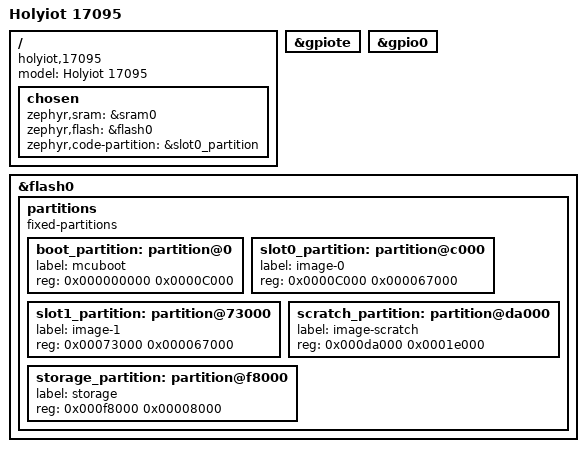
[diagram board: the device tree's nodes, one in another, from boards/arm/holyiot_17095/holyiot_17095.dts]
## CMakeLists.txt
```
# Boilerplate code, which pulls in the Zephyr build system.
cmake_minimum_required(VERSION 3.13.1)
include($ENV{ZEPHYR_BASE}/cmake/app/boilerplate.cmake NO_POLICY_SCOPE)
project(mesh-onoff)

# Add your source file to the "app" target. This must come after
# the boilerplate code, which defines the target.
target_sources(app PRIVATE src/main.c)
```

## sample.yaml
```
sample:
  name: Bluetooth Mesh
tests:
  sample.bluetooth.mesh.onoff:
    platform_whitelist: nrf52_blenano2
    tags: bluetooth
    harness: bluetooth
```

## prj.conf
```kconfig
CONFIG_MAIN_STACK_SIZE=512
CONFIG_SYSTEM_WORKQUEUE_STACK_SIZE=2048
CONFIG_GPIO=y
CONFIG_BT_SETTINGS=y
CONFIG_FLASH=y
CONFIG_FLASH_PAGE_LAYOUT=y
CONFIG_FLASH_MAP=y
CONFIG_NVS=y
CONFIG_SETTINGS=y
CONFIG_BT_MESH_RPL_STORE_TIMEOUT=600
CONFIG_BOOT_BANNER=y
CONFIG_BT_OBSERVER=y
CONFIG_BT_BROADCASTER=y
CONFIG_BT_CTLR_DUP_FILTER_LEN=0
CONFIG_BT_CTLR_LE_ENC=n
CONFIG_BT_CTLR_LE_PING=n
CONFIG_BT_DATA_LEN_UPDATE=n
CONFIG_BT_PHY_UPDATE=n
CONFIG_BT_CTLR_CHAN_SEL_2=n
CONFIG_BT_CTLR_MIN_USED_CHAN=n
CONFIG_BT_CTLR_ADV_EXT=n
CONFIG_BT_CTLR_PRIVACY=n
CONFIG_BT_PERIPHERAL=y
CONFIG_BT=y
CONFIG_BT_TINYCRYPT_ECC=y
CONFIG_BT_L2CAP_TX_BUF_COUNT=8
CONFIG_BT_MESH=y
CONFIG_BT_MESH_RELAY=y
CONFIG_BT_MESH_LOW_POWER=n
CONFIG_BT_MESH_FRIEND=n
CONFIG_BT_MESH_ADV_BUF_COUNT=20
CONFIG_BT_MESH_TX_SEG_MAX=6
CONFIG_BT_MESH_PB_GATT=y
CONFIG_BT_MESH_PB_ADV=y
CONFIG_BT_MESH_GATT_PROXY=y
CONFIG_BT_MESH_CFG_CLI=y
CONFIG_BT_MESH_SUBNET_COUNT=2
CONFIG_BT_MESH_APP_KEY_COUNT=2
CONFIG_BT_MESH_MODEL_KEY_COUNT=2
CONFIG_BT_MESH_MODEL_GROUP_COUNT=2
CONFIG_BT_MESH_LABEL_COUNT=3
CONFIG_UART_CONSOLE=y
CONFIG_BT_DEBUG_LOG=y
CONFIG_BT_MESH_DEBUG=y
CONFIG_BT_RX_STACK_SIZE=4096
CONFIG_BT_MAX_CONN=1
CONFIG_BT_CTLR_RX_BUFFERS=6
CONFIG_BT_CTLR_TX_BUFFERS=4
CONFIG_BT_HCI_CMD_COUNT=4
CONFIG_BT_ATT_PREPARE_COUNT=2
CONFIG_BT_CTLR_TX_PWR_PLUS_4=y
```

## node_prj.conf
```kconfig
CONFIG_INIT_STACKS=y
CONFIG_MAIN_STACK_SIZE=512
CONFIG_DISPLAY=y
CONFIG_SYSTEM_WORKQUEUE_STACK_SIZE=2048
CONFIG_GPIO=y

CONFIG_BT_SETTINGS=y
CONFIG_FLASH=y
CONFIG_FLASH_PAGE_LAYOUT=y
CONFIG_FLASH_MAP=y
CONFIG_NVS=y
CONFIG_SETTINGS=y

CONFIG_BT=y
CONFIG_BT_TINYCRYPT_ECC=y
CONFIG_BT_RX_STACK_SIZE=1100
CONFIG_BT_RX_BUF_COUNT=3
CONFIG_BT_DISCARDABLE_BUF_COUNT=3

CONFIG_BT_CTLR_DUP_FILTER_LEN=0
CONFIG_BT_OBSERVER=y
CONFIG_BT_BROADCASTER=y

CONFIG_BT_CTLR_LE_ENC=n
CONFIG_BT_CTLR_LE_PING=n
CONFIG_BT_DATA_LEN_UPDATE=n
CONFIG_BT_PHY_UPDATE=n
CONFIG_BT_CTLR_CHAN_SEL_2=n
CONFIG_BT_CTLR_MIN_USED_CHAN=n
CONFIG_BT_CTLR_ADV_EXT=n
CONFIG_BT_CTLR_PRIVACY=n

CONFIG_BT_MESH=y
CONFIG_BT_MESH_RX_SDU_MAX=36
CONFIG_BT_MESH_RELAY=y

#CONFIG_BT_MESH_LOW_POWER=y

#CONFIG_BT_MESH_SELF_TEST=y
#CONFIG_BT_MESH_IV_UPDATE_TEST=y

CONFIG_BT_MESH_SUBNET_COUNT=1
CONFIG_BT_MESH_APP_KEY_COUNT=1
CONFIG_BT_MESH_MODEL_GROUP_COUNT=1
CONFIG_BT_MESH_LABEL_COUNT=0

#CONFIG_BT_DEBUG_LOG=y

#CONFIG_BT_MESH_DEBUG=y
#CONFIG_BT_MESH_DEBUG_NET=y
#CONFIG_BT_MESH_DEBUG_TRANS=y
#CONFIG_BT_MESH_DEBUG_PROV=y
#CONFIG_BT_MESH_DEBUG_BEACON=y
#CONFIG_BT_MESH_DEBUG_CRYPTO=y
#CONFIG_BT_MESH_DEBUG_ADV=y
#CONFIG_BT_MESH_DEBUG_ACCESS=y
```

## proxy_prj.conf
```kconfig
#CONFIG_INIT_STACKS=y
CONFIG_SYSTEM_WORKQUEUE_STACK_SIZE=2048

CONFIG_BT_SETTINGS=y
CONFIG_FLASH=y
CONFIG_FLASH_PAGE_LAYOUT=y
CONFIG_FLASH_MAP=y
CONFIG_NVS=y
CONFIG_SETTINGS=y

CONFIG_BT_OBSERVER=y
CONFIG_BT_BROADCASTER=y
CONFIG_BT_CTLR_DUP_FILTER_LEN=0
CONFIG_BT_CTLR_LE_ENC=n
CONFIG_BT_CTLR_LE_PING=n
CONFIG_BT_DATA_LEN_UPDATE=n
CONFIG_BT_PHY_UPDATE=n
CONFIG_BT_CTLR_CHAN_SEL_2=n
CONFIG_BT_CTLR_MIN_USED_CHAN=n
CONFIG_BT_CTLR_ADV_EXT=n
CONFIG_BT_CTLR_PRIVACY=n

CONFIG_BT_PERIPHERAL=y

CONFIG_BT=y
CONFIG_BT_TINYCRYPT_ECC=y
CONFIG_BT_L2CAP_RX_MTU=69
CONFIG_BT_L2CAP_TX_MTU=69
CONFIG_BT_L2CAP_TX_BUF_COUNT=5

CONFIG_BT_MESH=y
CONFIG_BT_MESH_RELAY=y
CONFIG_BT_MESH_LOW_POWER=n
CONFIG_BT_MESH_FRIEND=y
CONFIG_BT_MESH_FRIEND_QUEUE_SIZE=16

CONFIG_BT_MESH_PB_GATT=y
CONFIG_BT_MESH_PB_ADV=y
CONFIG_BT_MESH_GATT_PROXY=y

#CONFIG_BT_MESH_LPN_SCAN_LATENCY=30
#CONFIG_BT_MESH_LPN_RECV_DELAY=40
#CONFIG_BT_MESH_LPN_POLL_TIMEOUT=300

CONFIG_BT_MESH_SUBNET_COUNT=2
CONFIG_BT_MESH_APP_KEY_COUNT=2
CONFIG_BT_MESH_MODEL_GROUP_COUNT=2
CONFIG_BT_MESH_LABEL_COUNT=3

#CONFIG_BT_MESH_IV_UPDATE_TEST=y

#CONFIG_UART_CONSOLE=n
#CONFIG_BT_DEBUG_MONITOR=y
CONFIG_BT_DEBUG_LOG=y

CONFIG_BT_MESH_DEBUG=y
#CONFIG_BT_MESH_DEBUG_PROV=y
#CONFIG_BT_MESH_DEBUG_PROXY=y
#CONFIG_BT_MESH_DEBUG_BEACON=y
CONFIG_BT_MESH_DEBUG_NET=y
CONFIG_BT_MESH_DEBUG_TRANS=y
CONFIG_BT_MESH_DEBUG_SETTINGS=y
#CONFIG_BT_MESH_DEBUG_LOW_POWER=y
CONFIG_BT_MESH_DEBUG_FRIEND=y
#CONFIG_BT_MESH_DEBUG_MODEL=y
#CONFIG_BT_MESH_DEBUG_ACCESS=y
#CONFIG_BT_MESH_DEBUG_CRYPTO=y
#CONFIG_BT_MESH_DEBUG_ADV=y
#CONFIG_BT_MESH_SELF_TEST=y
CONFIG_BT_CTLR_TX_PWR_PLUS_4=y
```

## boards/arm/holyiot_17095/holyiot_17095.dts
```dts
/*
 * Copyright (c) 2019 Henrik Brix Andersen <henrik@brixandersen.dk>
 *
 * SPDX-License-Identifier: Apache-2.0
 */

/dts-v1/;
#include <nordic/nrf52832_qfaa.dtsi>

/ {
	model = "Holyiot 17095";
	compatible = "holyiot,17095", "nordic,nrf52832-qfaa",
		     "nordic,nrf52832";

	chosen {
		zephyr,sram = &sram0;
		zephyr,flash = &flash0;
		zephyr,code-partition = &slot0_partition;
	};
};

&gpiote {
	status = "okay";
};

&gpio0 {
	status = "okay";
};

&flash0 {
	/*
	 * For more information, see:
	 * http://docs.zephyrproject.org/latest/guides/dts/index.html#flash-partitions
	 */
	partitions {
		compatible = "fixed-partitions";
		#address-cells = <1>;
		#size-cells = <1>;

		boot_partition: partition@0 {
			label = "mcuboot";
			reg = <0x000000000 0x0000C000>;
		};
		slot0_partition: partition@c000 {
			label = "image-0";
			reg = <0x0000C000 0x000067000>;
		};
		slot1_partition: partition@73000 {
			label = "image-1";
			reg = <0x00073000 0x000067000>;
		};
		scratch_partition: partition@da000 {
			label = "image-scratch";
			reg = <0x000da000 0x0001e000>;
		};

		/*
		 * The flash starting at 0x000f8000 and ending at
		 * 0x000fffff is reserved for use by the application.
		 */

		/* Storage partition will be used by FCB/NFFS/NVS if enabled. */
		storage_partition: partition@f8000 {
			label = "storage";
			reg = <0x000f8000 0x00008000>;
		};
	};
};
```

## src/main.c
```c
#include <bluetooth/bluetooth.h>
#include "mesh_logic.h"
#include "ts_buttons_logic.h"
#include "relays_logic.h"
#include "leds_logic.h"

void main(void) {
  init_leds();
  init_relays();
  init_ts();

  /* Initialize the Bluetooth Subsystem */
  int err;
  err = bt_enable(bt_ready);
  if (err) {

  }
}
```

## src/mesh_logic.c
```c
#include <stdint.h>
#include <bluetooth/bluetooth.h>
#include <bluetooth/conn.h>
#include <bluetooth/hci.h>
#include <bluetooth/l2cap.h>
#include <bluetooth/mesh.h>
#include <settings/settings.h>
#include "mesh_logic.h"
#include "relays_logic.h"
#include "node_conf.h"


/* Model Operation Codes */
#define BT_MESH_MODEL_OP_GEN_ONOFF_GET        BT_MESH_MODEL_OP_2(0x82, 0x01)
#define BT_MESH_MODEL_OP_GEN_ONOFF_SET        BT_MESH_MODEL_OP_2(0x82, 0x02)
#define BT_MESH_MODEL_OP_GEN_ONOFF_SET_UNACK  BT_MESH_MODEL_OP_2(0x82, 0x03)
#define BT_MESH_MODEL_OP_GEN_ONOFF_STATUS     BT_MESH_MODEL_OP_2(0x82, 0x04)

static void gen_onoff_set(struct bt_mesh_model *model, struct bt_mesh_msg_ctx *ctx, struct net_buf_simple *buf);
static void gen_onoff_set_unack(struct bt_mesh_model *model, struct bt_mesh_msg_ctx *ctx, struct net_buf_simple *buf);
static void gen_onoff_get(struct bt_mesh_model *model, struct bt_mesh_msg_ctx *ctx, struct net_buf_simple *buf);
static void gen_onoff_status(struct bt_mesh_model *model, struct bt_mesh_msg_ctx *ctx, struct net_buf_simple *buf);

/*
 * Server Configuration Declaration
 */

static struct bt_mesh_cfg_srv cfg_srv = {
  .relay = BT_MESH_RELAY_DISABLED,
  .beacon = BT_MESH_BEACON_ENABLED,
#if defined(CONFIG_BT_MESH_FRIEND)
  .frnd = BT_MESH_FRIEND_ENABLED,
#else
  .frnd = BT_MESH_FRIEND_NOT_SUPPORTED,
#endif
#if defined(CONFIG_BT_MESH_GATT_PROXY)
  .gatt_proxy = BT_MESH_GATT_PROXY_ENABLED,
#else
  .gatt_proxy = BT_MESH_GATT_PROXY_NOT_SUPPORTED,
#endif
  .default_ttl = 7,

  /* 3 transmissions with 20ms interval */
  .net_transmit = BT_MESH_TRANSMIT(2, 20),
  .relay_retransmit = BT_MESH_TRANSMIT(2, 20)
};

/*
 * Client Configuration Declaration
 */

static struct bt_mesh_cfg_cli cfg_cli = {};

/*
 * Health Server Declaration
 */

static struct bt_mesh_health_srv health_srv = {};

/*
 * Publication Declarations
 *
 * The publication messages are initialized to the
 * the size of the opcode + content
 *
 * For publication, the message must be in static or global as
 * it is re-transmitted several times. This occurs
 * after the function that called bt_mesh_model_publish() has
 * exited and the stack is no longer valid.
 *
 * Note that the additional 4 bytes for the AppMIC is not needed
 * because it is added to a stack variable at the time a
 * transmission occurs.
 *
 */

BT_MESH_HEALTH_PUB_DEFINE(health_pub, 0);

BT_MESH_MODEL_PUB_DEFINE(gen_onoff_pub_srv_ch1, NULL, 2 + 1);
BT_MESH_MODEL_PUB_DEFINE(gen_onoff_pub_cli_ch1, NULL, 2 + 1);

#if LIGHT_CHANNELS == 2
BT_MESH_MODEL_PUB_DEFINE(gen_onoff_pub_srv_ch2, NULL, 2 + 1);
BT_MESH_MODEL_PUB_DEFINE(gen_onoff_pub_cli_ch2, NULL, 2 + 1);
#endif

/*
 * Models in an element must have unique op codes.
 *
 * The mesh stack dispatches a message to the first model in an element
 * that is also bound to an app key and supports the op code in the
 * received message.
 *
 */

/*
 * OnOff Model Server Op Dispatch Table
 *
 */

static const struct bt_mesh_model_op gen_onoff_srv_op[] = {
  { BT_MESH_MODEL_OP_GEN_ONOFF_GET, 0, gen_onoff_get },
  { BT_MESH_MODEL_OP_GEN_ONOFF_SET, 1, gen_onoff_set },
  { BT_MESH_MODEL_OP_GEN_ONOFF_SET_UNACK, 1, gen_onoff_set_unack },
  BT_MESH_MODEL_OP_END
};

/*
 * OnOff Model Client Op Dispatch Table
 */

static const struct bt_mesh_model_op gen_onoff_cli_op[] = {
  { BT_MESH_MODEL_OP_GEN_ONOFF_STATUS, 1, gen_onoff_status },
  BT_MESH_MODEL_OP_END
};

/*
 *
 * Element Model Declarations
 *
 * Element 0 Root Models
 */

static uint8_t light_channel_idx[] = {
  0,
#if LIGHT_CHANNELS == 2
  1,
#endif
};

static struct bt_mesh_model root_models[] = {
  BT_MESH_MODEL_CFG_SRV(&cfg_srv),
  BT_MESH_MODEL_CFG_CLI(&cfg_cli),
  BT_MESH_MODEL_HEALTH_SRV(&health_srv, &health_pub)
};

static struct bt_mesh_model secondary_models_ch1[] = {
  BT_MESH_MODEL(BT_MESH_MODEL_ID_GEN_ONOFF_SRV, gen_onoff_srv_op, &gen_onoff_pub_srv_ch1, &light_channel_idx[0]),
  BT_MESH_MODEL(BT_MESH_MODEL_ID_GEN_ONOFF_CLI, gen_onoff_cli_op, &gen_onoff_pub_cli_ch1, &light_channel_idx[0])
};

#if LIGHT_CHANNELS == 2
static struct bt_mesh_model secondary_models_ch2[] = {
  BT_MESH_MODEL(BT_MESH_MODEL_ID_GEN_ONOFF_SRV, gen_onoff_srv_op, &gen_onoff_pub_srv_ch2, &light_channel_idx[1]),
  BT_MESH_MODEL(BT_MESH_MODEL_ID_GEN_ONOFF_CLI, gen_onoff_cli_op, &gen_onoff_pub_cli_ch2, &light_channel_idx[1])
};
#endif


/*
 * Button to Client Model Assignments
 */

static struct bt_mesh_model *mod_cli_ts_btn[] = {
  &secondary_models_ch1[1],
#if LIGHT_CHANNELS == 2
  &secondary_models_ch2[1],
#endif
};

/*
 * Root Element Declarations
 */

static struct bt_mesh_elem elements[] = {
  BT_MESH_ELEM(0, root_models, BT_MESH_MODEL_NONE),
  BT_MESH_ELEM(0, secondary_models_ch1, BT_MESH_MODEL_NONE),
#if LIGHT_CHANNELS == 2
  BT_MESH_ELEM(0, secondary_models_ch2, BT_MESH_MODEL_NONE),
#endif
};

static const struct bt_mesh_comp comp = {
  .cid = BT_COMP_ID_LF,
  .elem = elements,
  .elem_count = ARRAY_SIZE(elements)
};

static uint16_t primary_addr;
static uint16_t primary_net_idx;

/*
 * Generic OnOff Model Server Message Handlers
 *
 * Mesh Model Specification 3.1.1
 *
 */

static void gen_onoff_get(struct bt_mesh_model *model, struct bt_mesh_msg_ctx *ctx, struct net_buf_simple *buf) {
  NET_BUF_SIMPLE_DEFINE(msg, 2 + 1 + 4);

  uint8_t *channel = (uint8_t*)model->user_data;

  bt_mesh_model_msg_init(&msg, BT_MESH_MODEL_OP_GEN_ONOFF_STATUS);
  net_buf_simple_add_u8(&msg, get_relay_state(*channel));

  if (bt_mesh_model_send(model, ctx, &msg, NULL, NULL)) {

  }
}

static void gen_onoff_set_unack(struct bt_mesh_model *model, struct bt_mesh_msg_ctx *ctx, struct net_buf_simple *buf) {
  struct net_buf_simple *msg = model->pub->msg;
  uint8_t *channel = (uint8_t *)model->user_data;

  set_relay_state(*channel, net_buf_simple_pull_u8(buf));

  if (model->pub->addr != BT_MESH_ADDR_UNASSIGNED) {
    bt_mesh_model_msg_init(msg, BT_MESH_MODEL_OP_GEN_ONOFF_STATUS);
    net_buf_simple_add_u8(msg, get_relay_state(*channel));
    int err = bt_mesh_model_publish(model);
    if (err) {

    }
  }
}

static void gen_onoff_set(struct bt_mesh_model *model, struct bt_mesh_msg_ctx *ctx, struct net_buf_simple *buf) {
  printk("gen_onoff_set\n");

  gen_onoff_set_unack(model, ctx, buf);
  gen_onoff_get(model, ctx, buf);
}

static void gen_onoff_status(struct bt_mesh_model *model, struct bt_mesh_msg_ctx *ctx, struct net_buf_simple *buf) {

}

static void prov_complete(u16_t net_idx, u16_t addr) {
  primary_addr = addr;
  primary_net_idx = net_idx;
}

static void prov_reset(void) {
  bt_mesh_prov_enable(BT_MESH_PROV_ADV | BT_MESH_PROV_GATT);
}

static uint8_t dev_uuid[16] = {0xdd, 0xdd};

/* Disable OOB security */

static const struct bt_mesh_prov prov = {
  .uuid = dev_uuid,
  .output_size = 0,
  .output_actions = 0,
  .output_number = 0,
  .complete = prov_complete,
  .reset = prov_reset
};

/*
 * Bluetooth Ready Callback
 */

void bt_ready(int err) {
  struct bt_le_oob oob;

  if (err) {
    return;
  }

  err = bt_mesh_init(&prov, &comp);
  if (err) {;
    return;
  }

  if (IS_ENABLED(CONFIG_SETTINGS)) {
    settings_load();
  }

  /* Use identity address as device UUID */
  if (bt_le_oob_get_local(BT_ID_DEFAULT, &oob)) {

  } else {
    memcpy(dev_uuid, oob.addr.a.val, 6);
  }

  bt_mesh_prov_enable(BT_MESH_PROV_GATT | BT_MESH_PROV_ADV);
}

void mesh_publish_state(uint8_t channel, uint8_t new_state) {
  struct bt_mesh_model *mod_cli = mod_cli_ts_btn[channel];
  struct bt_mesh_model_pub *pub_cli = mod_cli->pub;

  if (pub_cli->addr == BT_MESH_ADDR_UNASSIGNED) {
    return;
  }

  bt_mesh_model_msg_init(pub_cli->msg, BT_MESH_MODEL_OP_GEN_ONOFF_SET);
  net_buf_simple_add_u8(pub_cli->msg, new_state);

  int err = bt_mesh_model_publish(mod_cli);
  if (err) {

  }
}
```

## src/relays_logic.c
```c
#include <stdint.h>
#include <device.h>
#include <drivers/gpio.h>
#include "relays_logic.h"
#include "leds_logic.h"
#include "mesh_logic.h"
#include "node_conf.h"


#define OFF 0
#define ON  1

#define LOW  0
#define HIGH 1

#define RELAY_INIT_TIMEOUT_MS 1500
#define RELAY_TRIGGER_PULSE_DURATION_MS 20

static struct device *gpio_dev_port;
static uint8_t coil_pin;
static uint8_t ch_state[LIGHT_CHANNELS];

static uint8_t RELAY_COIL[][2] = {
  { RELAY1_RESET_PIN, RELAY1_SET_PIN },
#if LIGHT_CHANNELS == 2
  { RELAY2_RESET_PIN, RELAY2_SET_PIN }
#endif
};

static void relay_pulse_timeout(struct k_timer *tim);
K_TIMER_DEFINE(relay_pulse_timer, relay_pulse_timeout, NULL);

static void relay_init_timeout(struct k_timer *tim);
K_TIMER_DEFINE(relay_startup_timer, relay_init_timeout, NULL);


static void relay_pulse_timeout(struct k_timer *tim) {
  gpio_pin_write(gpio_dev_port, coil_pin, LOW);
}

uint8_t get_relay_state(uint8_t channel) {
  return ch_state[channel];
}

void set_relay_state(uint8_t channel, uint8_t new_state) {
  ch_state[channel] = new_state;
  coil_pin = RELAY_COIL[channel][new_state];

  gpio_pin_write(gpio_dev_port, coil_pin, HIGH);
  k_timer_start(&relay_pulse_timer, K_MSEC(RELAY_TRIGGER_PULSE_DURATION_MS), 0);
  set_led_state(new_state);
  mesh_publish_state(channel, ch_state[channel]);
}

void relay_toggle(uint8_t channel) {
  ch_state[channel] = !ch_state[channel];

  set_relay_state(channel, ch_state[channel]);
}

static void relay_init_timeout(struct k_timer *tim) {
#ifdef VSENSE_PIN
  uint32_t switch_state = 0;
  gpio_pin_read(gpio_dev_port, VSENSE_PIN, &switch_state);
#endif

#ifdef VSENSE_PIN
  if (switch_state == ON) {
#endif
    set_relay_state(LIGHT_CHANNEL_1_INDEX, OFF);
#if LIGHT_CHANNELS == 2
    set_relay_state(LIGHT_CHANNEL_2_INDEX, OFF);
#endif
#ifdef VSENSE_PIN
  }
#endif
}

void init_relays(void) {
  gpio_dev_port = device_get_binding("GPIO_0");

  // Channel 1 relay coils
  gpio_pin_configure(gpio_dev_port, RELAY1_SET_PIN, GPIO_DIR_OUT);
  gpio_pin_configure(gpio_dev_port, RELAY1_RESET_PIN, GPIO_DIR_OUT);
  gpio_pin_write(gpio_dev_port, RELAY1_SET_PIN, LOW);
  gpio_pin_write(gpio_dev_port, RELAY1_RESET_PIN, LOW);

#if LIGHT_CHANNELS == 2
  // Channel 2 relay coils
  gpio_pin_configure(gpio_dev_port, RELAY2_SET_PIN, GPIO_DIR_OUT);
  gpio_pin_configure(gpio_dev_port, RELAY2_RESET_PIN, GPIO_DIR_OUT);
  gpio_pin_write(gpio_dev_port, RELAY2_SET_PIN, LOW);
  gpio_pin_write(gpio_dev_port, RELAY2_RESET_PIN, LOW);
#endif

#ifdef VSENSE_PIN
  gpio_pin_configure(gpio_dev_port, VSENSE_PIN, (GPIO_DIR_IN | GPIO_PUD_NORMAL));
#endif

  // reset relays to the OFF state after some time when system starts
  k_timer_start(&relay_startup_timer, K_MSEC(RELAY_INIT_TIMEOUT_MS), 0);
}
```

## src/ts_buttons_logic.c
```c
#include <stdint.h>
#include <device.h>
#include <drivers/gpio.h>
#include <drivers/pwm.h>
#include "ts_buttons_logic.h"
#include "relays_logic.h"
#include "node_conf.h"

#define LOW  0
#define HIGH 1

#define PWM_DUTY_CYCLE_PERCENT 30
#define PWM_FREQUENCY_HZ 100000
#define PWM_PERIOD_USEC (1000000 / PWM_FREQUENCY_HZ)
#define PWM_PULSE_US (PWM_PERIOD_USEC * PWM_DUTY_CYCLE_PERCENT) / 100

#define BUTTON_DEBOUNCE_INTERVAL_MS 250

static struct gpio_callback ts_cb;

static void button_pressed(struct device *dev, struct gpio_callback *cb, u32_t pin_pos) {
  static uint32_t last_press_timestamp;

  // simple debouncing
  if ((k_uptime_get_32() - last_press_timestamp) >= BUTTON_DEBOUNCE_INTERVAL_MS) {
    // process TS1
    if (pin_pos == BIT(TS1_PIN)) {
      relay_toggle(LIGHT_CHANNEL_1_INDEX);
    }

#if LIGHT_CHANNELS == 2
    // process TS2
    if (pin_pos == BIT(TS2_PIN)) {
      relay_toggle(LIGHT_CHANNEL_2_INDEX);
    }
#endif

    last_press_timestamp = k_uptime_get_32();
  }
}

void init_ts(void) {
  struct device *gpio_dev_port = device_get_binding("GPIO_0");

  // Touch sensor power mode
#ifdef MTPM1_PIN
  gpio_pin_configure(gpio_dev_port, MTPM1_PIN, GPIO_DIR_OUT);
  gpio_pin_write(gpio_dev_port, MTPM1_PIN, HIGH);
#endif

  // Touch sensor sensitivity
  struct device *ts_pwm = device_get_binding("PWM_0");
  pwm_pin_set_usec(ts_pwm, MTSA1_PIN, PWM_PERIOD_USEC, PWM_PULSE_US);
#ifdef MTSA2_PIN
  pwm_pin_set_usec(ts_pwm, MTSA2_PIN, PWM_PERIOD_USEC, PWM_PULSE_US);
#endif

  // Touch sensor reading
  gpio_pin_configure(gpio_dev_port, TS1_PIN, (GPIO_DIR_IN | GPIO_INT | GPIO_INT_EDGE | GPIO_INT_ACTIVE_LOW | GPIO_PUD_PULL_UP));
  gpio_init_callback(&ts_cb, button_pressed, BIT(TS1_PIN));
#if LIGHT_CHANNELS == 2
  gpio_pin_configure(gpio_dev_port, TS2_PIN, (GPIO_DIR_IN | GPIO_INT | GPIO_INT_EDGE | GPIO_INT_ACTIVE_LOW | GPIO_PUD_PULL_UP));
  gpio_init_callback(&ts_cb, button_pressed, BIT(TS2_PIN));
#endif
  gpio_add_callback(gpio_dev_port, &ts_cb);
  gpio_pin_enable_callback(gpio_dev_port, TS1_PIN);
#if LIGHT_CHANNELS == 2
  gpio_pin_enable_callback(gpio_dev_port, TS2_PIN);
#endif
}
```
